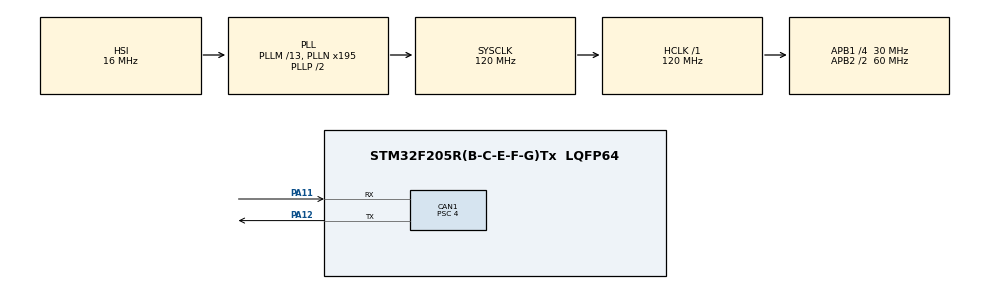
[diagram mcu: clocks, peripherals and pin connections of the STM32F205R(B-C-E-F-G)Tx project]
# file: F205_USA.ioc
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CAN1.AWUM=ENABLE
CAN1.BS1=CAN_BS1_12TQ
CAN1.BS2=CAN_BS2_2TQ
CAN1.CalculateBaudRate=499999
CAN1.CalculateTimeBit=2000
CAN1.CalculateTimeQuantum=133.33333333333334
CAN1.NART=ENABLE
CAN1.Prescaler=4
CAN1.TTCM=ENABLE
CAN1.TXFP=ENABLE
Mcu.Family=STM32F2
Mcu.Name=STM32F205R(B-C-E-F-G)Tx
Mcu.Package=LQFP64
NVIC.CAN1_RX0_IRQn=true\:0\:0\:false\:false\:true\:true\:true\:true
NVIC.PriorityGroup=NVIC_PRIORITYGROUP_4
PA11.Mode=CAN_Activate
PA11.Signal=CAN1_RX
PA12.Mode=CAN_Activate
PA12.Signal=CAN1_TX
PA13.Mode=Serial_Wire
PA13.Signal=SYS_JTMS-SWDIO
PA14.Mode=Serial_Wire
PA14.Signal=SYS_JTCK-SWCLK
PH0-OSC_IN.Mode=HSE-External-Oscillator
PH0-OSC_IN.Signal=RCC_OSC_IN
PH1-OSC_OUT.Mode=HSE-External-Oscillator
PH1-OSC_OUT.Signal=RCC_OSC_OUT
ProjectManager.HeapSize=0x200
ProjectManager.StackSize=0x400
ProjectManager.TargetToolchain=STM32CubeIDE
RCC.48MHZClocksFreq_Value=60000000
RCC.AHBFreq_Value=120000000
RCC.APB1CLKDivider=RCC_HCLK_DIV4
RCC.APB1Freq_Value=30000000
RCC.APB1TimFreq_Value=60000000
RCC.APB2CLKDivider=RCC_HCLK_DIV2
RCC.APB2Freq_Value=60000000
RCC.APB2TimFreq_Value=120000000
RCC.CortexFreq_Value=120000000
RCC.HCLKFreq_Value=120000000
RCC.HSE_VALUE=8000000
RCC.HSI_VALUE=16000000
RCC.LSE_VALUE=32768
RCC.PLLM=13
RCC.PLLN=195
RCC.SYSCLKFreq_VALUE=120000000
RCC.SYSCLKSource=RCC_SYSCLKSOURCE_PLLCLK
RCC.VCOOutputFreq_Value=240000000
board=custom

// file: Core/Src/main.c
/* USER CODE BEGIN Header */
/**
 ******************************************************************************
 * @file           : main.c
 * @brief          : Main program body
 ******************************************************************************
 * @attention
 *
 * Copyright (c) 2022 STMicroelectronics.
 * All rights reserved.
 *
 * This software is licensed under terms that can be found in the LICENSE file
 * in the root directory of this software component.
 * If no LICENSE file comes with this software, it is provided AS-IS.
 *
 ******************************************************************************
 */
/* USER CODE END Header */
#include "main.h"

CAN_HandleTypeDef hcan1;

void SystemClock_Config(void);
static void MX_GPIO_Init(void);
static void MX_CAN1_Init(void);

/* USER CODE BEGIN 0 */
CAN_RxHeaderTypeDef rxHeader;  // CAN Bus Transmit Header
CAN_TxHeaderTypeDef txHeader;  // CAN Bus Receive Header
uint8_t canRx[8];              // CAN Bus Receive Buffer
CAN_FilterTypeDef canfil;      // CAN Bus Filter
uint32_t canMailbox;           // CAN Bus Mail box variable
uint8_t speed = 0;
uint8_t cnt_421 = 0;
uint8_t p_n = 0;
uint8_t gear = 0;
uint8_t p_n_422;
uint8_t hand_brake = 0xF9;				// Hand brake indicator, by default is ON

/* USER CODE END 0 */

int main(void) {

  /* MCU Configuration--------------------------------------------------------*/

  /* Reset of all peripherals, Initializes the Flash interface and the Systick.
   */
  HAL_Init();

  /* Configure the system clock */
  SystemClock_Config();

  /* Initialize all configured peripherals */
  MX_GPIO_Init();
  MX_CAN1_Init();

  /* Infinite loop */
  /* USER CODE BEGIN WHILE */
  while (1) {
    if (hand_brake == 0xF9) { // if hand brake is 0xF9 or ON - going to parking
      p_n_422 = 0x07;
      gear = 0x01;
    }
    else {
      p_n_422 = 0x01;			// else going to AT selector position 2 to avoid shifts
      gear = 0x02;				// Always second gear to avoid kick down
    //if (speed > 0 && speed < 5) gear = 0x01;
    //if (speed > 10 && speed < 100) gear = 0x02;
    //if (speed > 100) gear = 0x04;
    }
    txHeader.DLC = 8;
    txHeader.IDE = CAN_ID_STD;
    txHeader.RTR = CAN_RTR_DATA;
    uint8_t can_send_422[8] = {0, gear, p_n_422, 0, 0, 0, 0, 0x7d};
    txHeader.StdId = 0x422;
    txHeader.TransmitGlobalTime = DISABLE;
    HAL_CAN_AddTxMessage(&hcan1, &txHeader, can_send_422, &canMailbox);
    HAL_Delay(2);
    uint8_t can_send_421[8] = {0xff, 0, 0, cnt_421, 0, 0, 0, 0};
    txHeader.StdId = 0x421;
    txHeader.TransmitGlobalTime = DISABLE;
    HAL_CAN_AddTxMessage(&hcan1, &txHeader, can_send_421, &canMailbox);
    HAL_Delay(2);
    uint8_t can_send_420[8] = {
        0, gear * 0x10 + gear, 0x01, 0x37, 0, 0x40, hand_brake, 0x04};
    txHeader.StdId = 0x420;
    txHeader.TransmitGlobalTime = DISABLE;
    HAL_CAN_AddTxMessage(&hcan1, &txHeader, can_send_420, &canMailbox);
    HAL_Delay(2);
    cnt_421++;
    /* USER CODE END WHILE */

  }
}

void SystemClock_Config(void) {
  RCC_OscInitTypeDef RCC_OscInitStruct = {0};
  RCC_ClkInitTypeDef RCC_ClkInitStruct = {0};

  /** Initializes the RCC Oscillators according to the specified parameters
   * in the RCC_OscInitTypeDef structure.
   */
  RCC_OscInitStruct.OscillatorType = RCC_OSCILLATORTYPE_HSI;
  RCC_OscInitStruct.HSIState = RCC_HSI_ON;
  RCC_OscInitStruct.HSICalibrationValue = RCC_HSICALIBRATION_DEFAULT;
  RCC_OscInitStruct.PLL.PLLState = RCC_PLL_ON;
  RCC_OscInitStruct.PLL.PLLSource = RCC_PLLSOURCE_HSI;
  RCC_OscInitStruct.PLL.PLLM = 13;
  RCC_OscInitStruct.PLL.PLLN = 195;
  RCC_OscInitStruct.PLL.PLLP = RCC_PLLP_DIV2;
  RCC_OscInitStruct.PLL.PLLQ = 4;
  if (HAL_RCC_OscConfig(&RCC_OscInitStruct) != HAL_OK) {
    Error_Handler();
  }

  /** Initializes the CPU, AHB and APB buses clocks
   */
  RCC_ClkInitStruct.ClockType = RCC_CLOCKTYPE_HCLK | RCC_CLOCKTYPE_SYSCLK |
                                RCC_CLOCKTYPE_PCLK1 | RCC_CLOCKTYPE_PCLK2;
  RCC_ClkInitStruct.SYSCLKSource = RCC_SYSCLKSOURCE_PLLCLK;
  RCC_ClkInitStruct.AHBCLKDivider = RCC_SYSCLK_DIV1;
  RCC_ClkInitStruct.APB1CLKDivider = RCC_HCLK_DIV4;
  RCC_ClkInitStruct.APB2CLKDivider = RCC_HCLK_DIV2;

  if (HAL_RCC_ClockConfig(&RCC_ClkInitStruct, FLASH_LATENCY_3) != HAL_OK) {
    Error_Handler();
  }
}

static void MX_CAN1_Init(void) {

  hcan1.Instance = CAN1;
  hcan1.Init.Prescaler = 4;
  hcan1.Init.Mode = CAN_MODE_NORMAL;
  hcan1.Init.SyncJumpWidth = CAN_SJW_1TQ;
  hcan1.Init.TimeSeg1 = CAN_BS1_12TQ;
  hcan1.Init.TimeSeg2 = CAN_BS2_2TQ;
  hcan1.Init.TimeTriggeredMode = ENABLE;
  hcan1.Init.AutoBusOff = DISABLE;
  hcan1.Init.AutoWakeUp = ENABLE;
  hcan1.Init.AutoRetransmission = ENABLE;
  hcan1.Init.ReceiveFifoLocked = DISABLE;
  hcan1.Init.TransmitFifoPriority = ENABLE;
  if (HAL_CAN_Init(&hcan1) != HAL_OK) {
    Error_Handler();
  }
  /* USER CODE BEGIN CAN1_Init 2 */
  canfil.FilterBank = 0;
  canfil.FilterMode = CAN_FILTERMODE_IDMASK;
  canfil.FilterFIFOAssignment = CAN_RX_FIFO0;
  canfil.FilterIdHigh = 0x0000;
  canfil.FilterIdLow = 0x0000;
  canfil.FilterMaskIdHigh = 0;
  canfil.FilterMaskIdLow = 0;
  canfil.FilterScale = CAN_FILTERSCALE_32BIT;
  canfil.FilterActivation = ENABLE;

  HAL_CAN_ConfigFilter(&hcan1, &canfil);
  HAL_CAN_Start(&hcan1);
  HAL_CAN_ActivateNotification(&hcan1, CAN_IT_RX_FIFO0_MSG_PENDING |
                                           CAN_IT_ERROR | CAN_IT_BUSOFF |
                                           CAN_IT_LAST_ERROR_CODE);
  /* USER CODE END CAN1_Init 2 */
}

static void MX_GPIO_Init(void) {
  /* GPIO Ports Clock Enable */
  __HAL_RCC_GPIOH_CLK_ENABLE();
  __HAL_RCC_GPIOA_CLK_ENABLE();
}

/* USER CODE BEGIN 4 */
void HAL_CAN_RxFifo0MsgPendingCallback(CAN_HandleTypeDef *hcan) {
  /////////////////////////////// CAN1 //////////////////////////////////////
  if (HAL_CAN_GetRxMessage(&hcan1, CAN_RX_FIFO0, &rxHeader, canRx) == HAL_OK) {
    if (rxHeader.StdId == 0x513) {
      speed = canRx[0] * 5 / 100 + canRx[1] * 0xff * 5 / 100;
    }
    if (rxHeader.StdId == 0x420) {		// Check hand brake state.
    	if (canRx[6] == 0xF9) {
    		hand_brake = 0xF9;			// Hand brake is ON
    	}
    	else if (canRx[6] == 0xFB) {
    	    hand_brake = 0xFB;			// Hand brake is OFF
    	}
    }
  }
}
/* USER CODE END 4 */

void Error_Handler(void) {
  __disable_irq();
  while (1) {
  }
}

#ifdef USE_FULL_ASSERT
/**
 * @brief  Reports the name of the source file and the source line number
 *         where the assert_param error has occurred.
 * @param  file: pointer to the source file name
 * @param  line: assert_param error line source number
 * @retval None
 */
void assert_failed(uint8_t *file, uint32_t line) {
  /* USER CODE BEGIN 6 */
  /* User can add his own implementation to report the file name and line
     number, ex: printf("Wrong parameters value: file %s on line %d\r\n", file,
     line) */
  /* USER CODE END 6 */
}
#endif /* USE_FULL_ASSERT */
